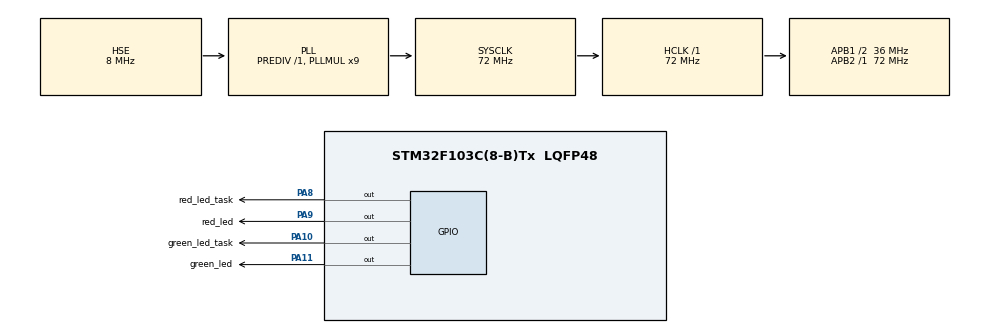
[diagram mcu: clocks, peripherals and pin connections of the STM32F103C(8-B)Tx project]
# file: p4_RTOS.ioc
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FREERTOS.Tasks01=defaultTask,24,128,StartDefaultTask,Default,NULL,Dynamic,NULL,NULL;green_Led,24,128,green_led,Default,NULL,Dynamic,NULL,NULL;red_Led,32,128,red_led,Default,NULL,Dynamic,NULL,NULL
FREERTOS.configUSE_NEWLIB_REENTRANT=1
Mcu.Family=STM32F1
Mcu.Name=STM32F103C(8-B)Tx
Mcu.Package=LQFP48
NVIC.PriorityGroup=NVIC_PRIORITYGROUP_4
NVIC.TIM4_IRQn=true\:15\:0\:false\:false\:true\:false\:false\:true\:true
NVIC.TimeBase=TIM4_IRQn
NVIC.TimeBaseIP=TIM4
PA10.GPIO_Label=green_led_task
PA10.Signal=GPIO_Output
PA11.GPIO_Label=green_led
PA11.Signal=GPIO_Output
PA13.Mode=Serial_Wire
PA13.Signal=SYS_JTMS-SWDIO
PA14.Mode=Serial_Wire
PA14.Signal=SYS_JTCK-SWCLK
PA8.GPIO_Label=red_led_task
PA8.Signal=GPIO_Output
PA9.GPIO_Label=red_led
PA9.Signal=GPIO_Output
PD0-OSC_IN.Mode=HSE-External-Oscillator
PD0-OSC_IN.Signal=RCC_OSC_IN
PD1-OSC_OUT.Mode=HSE-External-Oscillator
PD1-OSC_OUT.Signal=RCC_OSC_OUT
ProjectManager.HeapSize=0x200
ProjectManager.StackSize=0x400
ProjectManager.TargetToolchain=STM32CubeIDE
RCC.AHBFreq_Value=72000000
RCC.APB1CLKDivider=RCC_HCLK_DIV2
RCC.APB1Freq_Value=36000000
RCC.APB1TimFreq_Value=72000000
RCC.APB2Freq_Value=72000000
RCC.APB2TimFreq_Value=72000000
RCC.HCLKFreq_Value=72000000
RCC.PLLMUL=RCC_PLL_MUL9
RCC.PLLSourceVirtual=RCC_PLLSOURCE_HSE
RCC.SYSCLKFreq_VALUE=72000000
RCC.SYSCLKSource=RCC_SYSCLKSOURCE_PLLCLK
RCC.USBFreq_Value=72000000
VP_FREERTOS_VS_CMSIS_V2.Mode=CMSIS_V2
VP_SYS_VS_tim4.Mode=TIM4
board=custom

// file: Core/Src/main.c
/* USER CODE BEGIN Header */
/**
  ******************************************************************************
  * @file           : main.c
  * @brief          : Main program body
  ******************************************************************************
  * @attention
  *
  * Copyright (c) 2024 STMicroelectronics.
  * All rights reserved.
  *
  * This software is licensed under terms that can be found in the LICENSE file
  * in the root directory of this software component.
  * If no LICENSE file comes with this software, it is provided AS-IS.
  *
  ******************************************************************************
  */
/* USER CODE END Header */
#include "main.h"
#include "cmsis_os.h"

/* Definitions for defaultTask */
osThreadId_t defaultTaskHandle;
const osThreadAttr_t defaultTask_attributes = {
  .name = "defaultTask",
  .stack_size = 128 * 4,
  .priority = (osPriority_t) osPriorityNormal,
};
/* Definitions for green_Led */
osThreadId_t green_LedHandle;
const osThreadAttr_t green_Led_attributes = {
  .name = "green_Led",
  .stack_size = 128 * 4,
  .priority = (osPriority_t) osPriorityNormal,
};
/* Definitions for red_Led */
osThreadId_t red_LedHandle;
const osThreadAttr_t red_Led_attributes = {
  .name = "red_Led",
  .stack_size = 128 * 4,
  .priority = (osPriority_t) osPriorityAboveNormal,
};

void SystemClock_Config(void);
static void MX_GPIO_Init(void);
void StartDefaultTask(void *argument);
void green_led(void *argument);
void red_led(void *argument);

int main(void)
{

  /* MCU Configuration--------------------------------------------------------*/

  /* Reset of all peripherals, Initializes the Flash interface and the Systick. */
  HAL_Init();

  /* Configure the system clock */
  SystemClock_Config();

  /* Initialize all configured peripherals */
  MX_GPIO_Init();

  /* Init scheduler */
  osKernelInitialize();

  /* Create the thread(s) */
  /* creation of defaultTask */
  defaultTaskHandle = osThreadNew(StartDefaultTask, NULL, &defaultTask_attributes);

  /* creation of green_Led */
  green_LedHandle = osThreadNew(green_led, NULL, &green_Led_attributes);

  /* creation of red_Led */
  red_LedHandle = osThreadNew(red_led, NULL, &red_Led_attributes);

  /* Start scheduler */
  osKernelStart();

  /* We should never get here as control is now taken by the scheduler */

  /* Infinite loop */
  while (1)
  {

  }
}

void SystemClock_Config(void)
{
  RCC_OscInitTypeDef RCC_OscInitStruct = {0};
  RCC_ClkInitTypeDef RCC_ClkInitStruct = {0};

  /** Initializes the RCC Oscillators according to the specified parameters
  * in the RCC_OscInitTypeDef structure.
  */
  RCC_OscInitStruct.OscillatorType = RCC_OSCILLATORTYPE_HSE;
  RCC_OscInitStruct.HSEState = RCC_HSE_ON;
  RCC_OscInitStruct.HSEPredivValue = RCC_HSE_PREDIV_DIV1;
  RCC_OscInitStruct.HSIState = RCC_HSI_ON;
  RCC_OscInitStruct.PLL.PLLState = RCC_PLL_ON;
  RCC_OscInitStruct.PLL.PLLSource = RCC_PLLSOURCE_HSE;
  RCC_OscInitStruct.PLL.PLLMUL = RCC_PLL_MUL9;
  if (HAL_RCC_OscConfig(&RCC_OscInitStruct) != HAL_OK)
  {
    Error_Handler();
  }

  /** Initializes the CPU, AHB and APB buses clocks
  */
  RCC_ClkInitStruct.ClockType = RCC_CLOCKTYPE_HCLK|RCC_CLOCKTYPE_SYSCLK
                              |RCC_CLOCKTYPE_PCLK1|RCC_CLOCKTYPE_PCLK2;
  RCC_ClkInitStruct.SYSCLKSource = RCC_SYSCLKSOURCE_PLLCLK;
  RCC_ClkInitStruct.AHBCLKDivider = RCC_SYSCLK_DIV1;
  RCC_ClkInitStruct.APB1CLKDivider = RCC_HCLK_DIV2;
  RCC_ClkInitStruct.APB2CLKDivider = RCC_HCLK_DIV1;

  if (HAL_RCC_ClockConfig(&RCC_ClkInitStruct, FLASH_LATENCY_2) != HAL_OK)
  {
    Error_Handler();
  }
}

static void MX_GPIO_Init(void)
{
  GPIO_InitTypeDef GPIO_InitStruct = {0};

  __HAL_RCC_GPIOA_CLK_ENABLE();

  /* Configure GPIO pins: PA8 PA9 PA10 PA11 */
  GPIO_InitStruct.Pin = GPIO_PIN_8 | GPIO_PIN_9 | GPIO_PIN_10 | GPIO_PIN_11;
  GPIO_InitStruct.Mode = GPIO_MODE_OUTPUT_PP;  // Set as Output Push-Pull
  GPIO_InitStruct.Pull = GPIO_NOPULL;          // No pull-up or pull-down resistor
  GPIO_InitStruct.Speed = GPIO_SPEED_FREQ_LOW; // Low speed
  HAL_GPIO_Init(GPIOA, &GPIO_InitStruct);

  HAL_GPIO_WritePin(GPIOA, GPIO_PIN_8 | GPIO_PIN_9 | GPIO_PIN_10 | GPIO_PIN_11, GPIO_PIN_RESET);
}

void StartDefaultTask(void *argument)
{
  for(;;)
  {
    osDelay(1);
  }
}

void green_led(void *argument)
{
  /* USER CODE BEGIN green_led */
  /* Infinite loop */
	for (;;)
	  {
	    HAL_GPIO_WritePin(GPIOA, GPIO_PIN_11, GPIO_PIN_SET); // Blue LED ON (PA11)

	    for (int i = 0; i < 80; i++) {
	      HAL_GPIO_TogglePin(GPIOA, GPIO_PIN_9); // Toggle Green LED (PA9)
	      HAL_Delay(50);
	    }

	    HAL_GPIO_WritePin(GPIOA, GPIO_PIN_9, GPIO_PIN_RESET); // Green LED OFF
	    HAL_GPIO_WritePin(GPIOA, GPIO_PIN_11, GPIO_PIN_RESET); // Blue LED OFF

	    osDelay(6000);
  }
  /* USER CODE END green_led */
}

void red_led(void *argument)
{
  /* USER CODE BEGIN red_led */
  /* Infinite loop */
	for (;;)
	  {
	    HAL_GPIO_WritePin(GPIOA, GPIO_PIN_10, GPIO_PIN_SET); // Orange LED ON (PA10)

	    for (int i = 0; i < 10; i++) {
	      HAL_GPIO_TogglePin(GPIOA, GPIO_PIN_8); // Toggle Red LED (PA8)
	      HAL_Delay(50);
	    }

	    HAL_GPIO_WritePin(GPIOA, GPIO_PIN_8, GPIO_PIN_RESET); // Red LED OFF
	    HAL_GPIO_WritePin(GPIOA, GPIO_PIN_10, GPIO_PIN_RESET); // Orange LED OFF

	    osDelay(1500);
  }
  /* USER CODE END red_led */
}

void HAL_TIM_PeriodElapsedCallback(TIM_HandleTypeDef *htim)
{
  if (htim->Instance == TIM4) {
    HAL_IncTick();
  }
}

void Error_Handler(void)
{
  __disable_irq();
  while (1)
  {
  }
}
